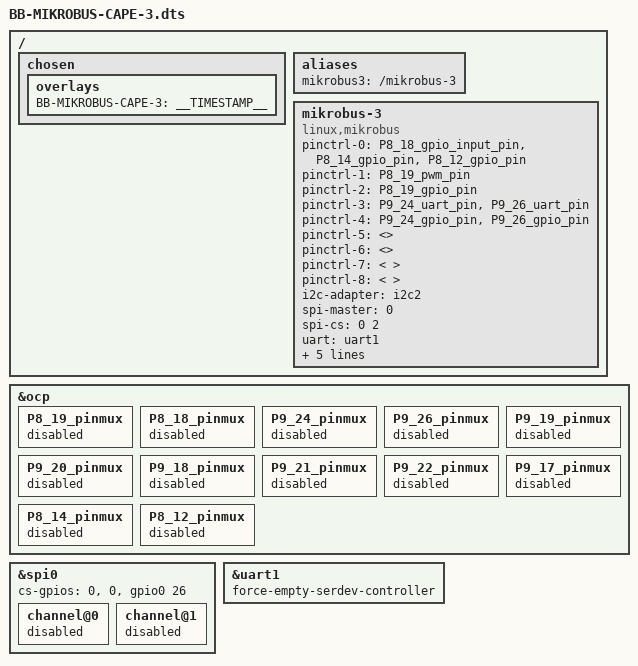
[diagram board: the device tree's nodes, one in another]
/*
 * Copyright (C) 2020 Robert Nelson <robertcnelson@gmail.com>
 * Copyright 2020 Vaishnav M A, BeagleBoard.org Foundation.
 *
 * This program is free software; you can redistribute it and/or modify
 * it under the terms of the GNU General Public License version 2 as
 * published by the Free Software Foundation.
 */

/dts-v1/;
/plugin/;

#include <dt-bindings/gpio/gpio.h>
#include <dt-bindings/pinctrl/am33xx.h>

/ {

	/*
	 * Helper to show loaded overlays under: /proc/device-tree/chosen/overlays/
	 */
	fragment@0 {
		target-path="/";
		__overlay__ {

			chosen {
				overlays {
					BB-MIKROBUS-CAPE-3 = __TIMESTAMP__;
				};
			};
		};
	};

	/*
	 * Free up the pins used by the mikrobus port from the pinmux helpers.
	 * pins are listed in clockwise order of their appearance in the
	 * mikrobus port.
	 */
	fragment@1 {
		target = <&ocp>;
		__overlay__ {			

			P8_19_pinmux { status = "disabled"; };
			P8_18_pinmux { status = "disabled"; };
			P9_24_pinmux { status = "disabled"; };
			P9_26_pinmux { status = "disabled"; };
			P9_19_pinmux { status = "disabled"; };
			P9_20_pinmux { status = "disabled"; };
			P9_18_pinmux { status = "disabled"; };
			P9_21_pinmux { status = "disabled"; };
			P9_22_pinmux { status = "disabled"; };
			P9_17_pinmux { status = "disabled"; };
			P8_14_pinmux { status = "disabled"; };
			P8_12_pinmux { status = "disabled"; };
		};
	};

	fragment@2 {
		target = <&spi0>;
		__overlay__ {
			status = "okay";
			cs-gpios = <0>, <0>, <&gpio0 26 GPIO_ACTIVE_HIGH>;
			channel@0{ status = "disabled"; };
			channel@1{ status = "disabled"; };
		};
	};

	fragment@3 {
		target = <&uart1>;
		__overlay__ {
			status = "okay";
			force-empty-serdev-controller;
		};
	};

	fragment@4 {
		target-path="/";
		__overlay__ {

			aliases {
				mikrobus3 = "/mikrobus-3";
			};
		};
	};

	fragment@5 {
		target-path="/";
		__overlay__ {
			mikrobus-3 {
				compatible = "linux,mikrobus";
				status = "okay";
				pinctrl-names = "default", "pwm_default", "pwm_gpio",
						"uart_default", "uart_gpio", "i2c_default",
						"i2c_gpio", "spi_default", "spi_gpio";
				pinctrl-0 = <
					&P8_18_gpio_input_pin
					&P8_14_gpio_pin
					&P8_12_gpio_pin
				>;
				pinctrl-1 = <&P8_19_pwm_pin>;
				pinctrl-2 = <&P8_19_gpio_pin>;		
				pinctrl-3 = <
					&P9_24_uart_pin
					&P9_26_uart_pin
				>;
				pinctrl-4 = <
					&P9_24_gpio_pin
					&P9_26_gpio_pin
				>;				
				pinctrl-5 = <>;/*hack, will be fixed in next mikrobus driver revision*/
				pinctrl-6 = <>;
				pinctrl-7 = <
				/* Enable below if UART/SPI Selectors are
				 * in SPI Position
				 */
				 /* disabled by default
					&P9_18_spi_pin
					&P9_21_spi_pin
					&P9_22_spi_sclk_pin
					&P9_17_spi_cs_pin
				*/
				>;
				pinctrl-8 = <
				/* disabled by default
					&P9_18_gpio_pin
					&P9_21_gpio_pin
					&P9_22_gpio_pin
					&P9_17_gpio_pin
				*/
				>;
				i2c-adapter = <&i2c2>;
				spi-master = <0>;
				spi-cs = <0 2>;
				uart = <&uart1>;
				pwms = <&ehrpwm2 0 500000 0>;
				mikrobus-gpios = <&gpio0 22 0> , <&gpio2 1 0>,
						 <&gpio0 15 0> , <&gpio0 14 0>,
						 <&gpio0 13 0> , <&gpio0 12 0>,
						 <&gpio0 4 0> , <&gpio0 3 0>,
						 <&gpio0 2 0> , <&gpio0 5 0>,
						 <&gpio0 26 0> , <&gpio1 12 0>;
			};
		};
	};
};
